# ATA6285 device description
Architecture: AVR8; Family: megaAVR
Programming and debug interfaces: ISP, HVPP, debugWIRE
Registers are 8-bit, access not given, no defined reset value unless marked. A register's access mark holds for its fields unless they carry their own. Offsets are from the block's base; lines under a group give offsets from that group; [hi:lo] are bit positions; {n}, {i} and the like mark numbered series; 'fields as' and 'values as' point back to an identical list; <NAME> marks a mode.

## Ordering variants
standard: 2.0 to 3.6 V

## Memory
prog space: start 0x0000 size 0x2000, little endian
  0x0000 FLASH size 0x2000 flash, rw, executable, page 0x40
  0x1f00 BOOT_SECTION_1 size 0x0100 flash, rw, executable, page 0x40
  0x1e00 BOOT_SECTION_2 size 0x0200 flash, rw, executable, page 0x40
  0x1c00 BOOT_SECTION_3 size 0x0400 flash, rw, executable, page 0x40
  0x1800 BOOT_SECTION_4 size 0x0800 flash, rw, executable, page 0x40
signatures space: start 0 size 3, little endian
  0 SIGNATURES size 3 signatures, ro
fuses space: start 0 size 0x0002, little endian
  0 FUSES size 0x0002 fuses, rw
lockbits space: start 0 size 0x0001, little endian
  0 LOCKBITS size 0x0001 lockbits, rw
data space: start 0x0000 size 0x0300, little endian
  0x0000 REGISTERS size 0x0020 regs
  0x0020 MAPPED_IO size 0x00e0 io
  0x0100 IRAM size 0x0200 ram
eeprom space: start 0x0000 size 0x0140, little endian
  0x0000 EEPROM size 0x0140 eeprom, rw, page 0x04
io space: start 0x00 size 0x40, little endian

## Peripheral instances (address, pins/pin function, parameters)
SENSOR_INTERFACE at 0x00
SPI at 0x00
CPU at 0x00
  parameters: CORE_VERSION=V2E
LFRX at 0x00
EXTERNAL_INTERRUPT at 0x00
PORTB at 0x00
PORTD at 0x00
TIMER_COUNTER_1 at 0x00
TIMER_COUNTER_2 at 0x00
TIMER_COUNTER_3 at 0x00
WDT at 0x00 — Watchdog Timer
TIMER_COUNTER_0 at 0x00
EEPROM at 0x00
PORTC at 0x00
FUSE at 0 in fuses
LOCKBIT at 0 in lockbits

## Interrupts
0 RESET — External Pin, Power-on Reset, Brown-out Reset, Watchdog Reset and Temperature Shutdown Reset
1 INT0 — External Interrupt Request 0
2 INT1 — External Interrupt Request 1
3 PCINT0 — Pin Change Interrupt Request 0
4 PCINT1 — Pin Change Interrupt Request 1
5 PCINT2 — Pin Change Interrupt Request 2
6 INTVM — Voltage Monitor Interrupt
7 SENINT — Sensor Interface Interrupt
8 INTT0 — Timer0 Interval Interrupt
9 LFWP — LF-Receiver Wake-up Interrupt
10 T3CAP — Timer/Counter3 Capture Event
11 T3COMA — Timer/Counter3 Compare Match A
12 T3COMB — Timer/Counter3 Compare Match B
13 T3OVF — Timer/Counter3 Overflow
14 T2CAP — Timer/Counter2 Capture Event
15 T2COM — Timer/Counter2 Compare Match
16 T2OVF — Timer/Counter2 Overflow
17 SPISTC — SPI Serial Transfer Complete
18 LFRXB — LF Receive Buffer Interrupt
19 INTT1 — Timer1 Interval Interrupt
20 T2RXB — Timer2 SSI Receive Buffer Interrupt
21 T2TXB — Timer2 SSI Transmit Buffer Interrupt
22 T2TXC — Timer2 SSI Transmit Complete Interrupt
23 LFREOB — LF-Receiver End of Burst Interrupt
24 EXCM — External Input Clock break down Interrupt
25 EEREADY — EEPROM Ready Interrupt
26 SPM_RDY — Store Program Memory Ready

## Properties
SIGNATURES: JTAGID=0x9382, SIGNATURE0=0x1e, SIGNATURE1=0x93, SIGNATURE2=0x82
OCD: OCD_REVISION=1, OCD_DATAREG=0x31, PROGBASE=0x0000

## FUSE
Instances: FUSE 0 in fuses
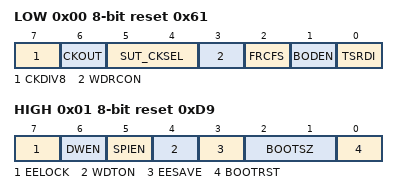
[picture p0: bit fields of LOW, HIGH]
0x00 LOW reset 0x61
  [7] CKDIV8 — Divide clock by 8 internally
  [6] CKOUT — Clock output on PORTC1
  [5:4] SUT_CKSEL — Select Clock Source
    0=START_UP_TIME_PWRDWN_RESET_6_CK_14_CK_0_MS_SUT_00; 1=START_UP_TIME_PWRDWN_RESET_6_CK_14_CK_5_7_MS_SUT_01; 2=START_UP_TIME_PWRDWN_RESET_6_CK_14_CK_90_MS_SUT_10
  [3] WDRCON — Enable Watchdog RC-Oscillator
  [2] FRCFS — Fast RC-Oscillator Frequency select
  [1] BODEN — Brown-out detection enabled
  [0] TSRDI — Disable Temperatur shutdown Reset
0x01 HIGH reset 0xD9
  [7] EELOCK — Upper EEPROM Locked (disabled)
  [6] DWEN — Debug Wire enable
  [5] SPIEN — Serial program downloading (SPI) enabled
  [4] WDTON — Watch-dog Timer always on
  [3] EESAVE — Preserve EEPROM through the Chip Erase cycle
  [2:1] BOOTSZ — Boot size select
    3=BOOT_SIZE_128_WORDS; 2=BOOT_SIZE_256_WORDS; 1=BOOT_SIZE_512_WORDS; 0=BOOT_SIZE_1024_WORDS
  [0] BOOTRST — Select reset vector
